# ioam3358 register map
Registers are 32-bit, access not given, no defined reset value unless marked. A register's access mark holds for its fields unless they carry their own. Addresses are absolute; registers are grouped by the start of their names; [hi:lo] are bit positions.

## USB0
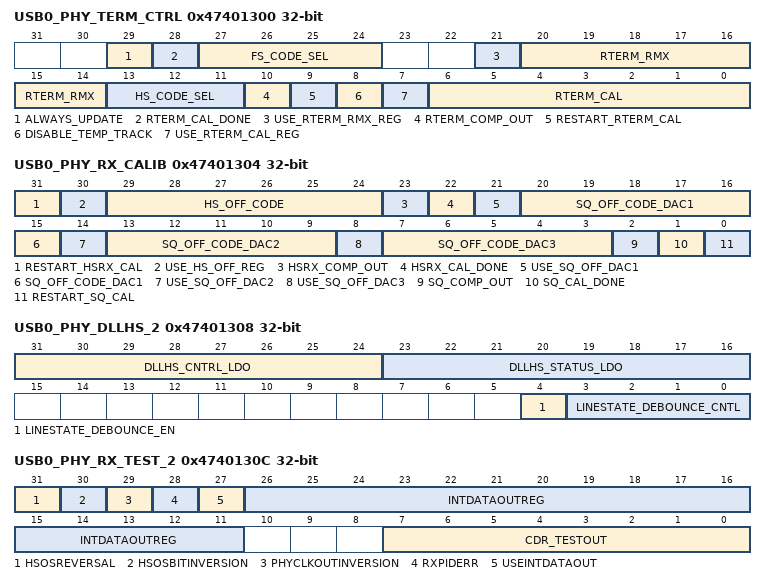
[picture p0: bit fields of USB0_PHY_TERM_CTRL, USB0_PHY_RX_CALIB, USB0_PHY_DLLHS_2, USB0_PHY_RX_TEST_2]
0x47401300 USB0_PHY_TERM_CTRL
  [29] ALWAYS_UPDATE, [28] RTERM_CAL_DONE, [27:24] FS_CODE_SEL, [21] USE_RTERM_RMX_REG, [20:14] RTERM_RMX, [13:11] HS_CODE_SEL, [10] RTERM_COMP_OUT, [9] RESTART_RTERM_CAL, [8] DISABLE_TEMP_TRACK, [7] USE_RTERM_CAL_REG, [6:0] RTERM_CAL
0x47401304 USB0_PHY_RX_CALIB
  [31] RESTART_HSRX_CAL, [30] USE_HS_OFF_REG, [29:24] HS_OFF_CODE, [23] HSRX_COMP_OUT, [22] HSRX_CAL_DONE, [21] USE_SQ_OFF_DAC1, [20:15] SQ_OFF_CODE_DAC1, [14] USE_SQ_OFF_DAC2, [13:9] SQ_OFF_CODE_DAC2, [8] USE_SQ_OFF_DAC3, [7:3] SQ_OFF_CODE_DAC3, [2] SQ_COMP_OUT, [1] SQ_CAL_DONE, [0] RESTART_SQ_CAL
0x47401308 USB0_PHY_DLLHS_2
  [31:24] DLLHS_CNTRL_LDO, [23:16] DLLHS_STATUS_LDO, [4] LINESTATE_DEBOUNCE_EN, [3:0] LINESTATE_DEBOUNCE_CNTL
0x4740130C USB0_PHY_RX_TEST_2
  [31] HSOSREVERSAL, [30] HSOSBITINVERSION, [29] PHYCLKOUTINVERSION, [28] RXPIDERR, [27] USEINTDATAOUT, [26:11] INTDATAOUTREG, [7:0] CDR_TESTOUT
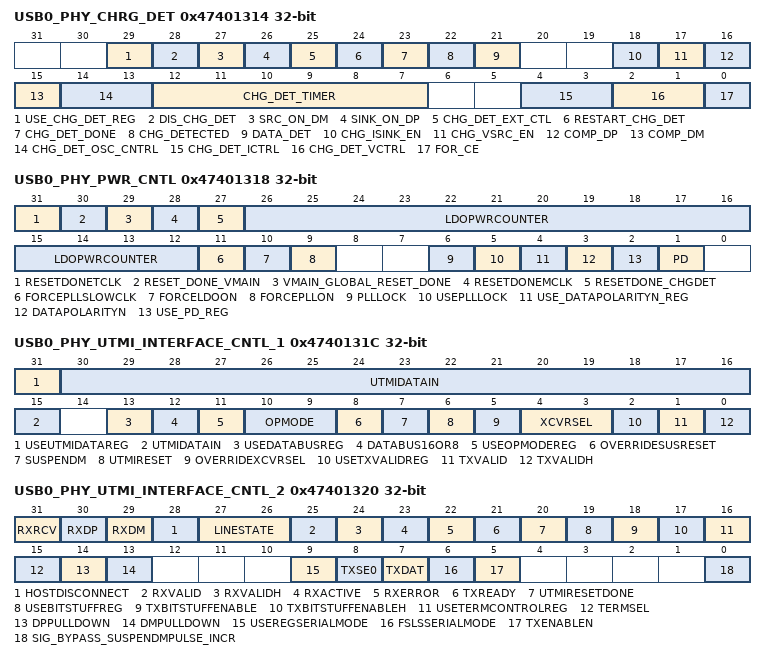
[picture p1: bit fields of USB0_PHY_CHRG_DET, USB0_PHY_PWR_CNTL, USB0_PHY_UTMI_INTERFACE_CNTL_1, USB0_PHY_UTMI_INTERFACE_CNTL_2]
0x47401314 USB0_PHY_CHRG_DET
  [29] USE_CHG_DET_REG, [28] DIS_CHG_DET, [27] SRC_ON_DM, [26] SINK_ON_DP, [25] CHG_DET_EXT_CTL, [24] RESTART_CHG_DET, [23] CHG_DET_DONE, [22] CHG_DETECTED, [21] DATA_DET, [18] CHG_ISINK_EN, [17] CHG_VSRC_EN, [16] COMP_DP, [15] COMP_DM, [14:13] CHG_DET_OSC_CNTRL, [12:7] CHG_DET_TIMER, [4:3] CHG_DET_ICTRL, [2:1] CHG_DET_VCTRL, [0] FOR_CE
0x47401318 USB0_PHY_PWR_CNTL
  [31] RESETDONETCLK, [30] RESET_DONE_VMAIN, [29] VMAIN_GLOBAL_RESET_DONE, [28] RESETDONEMCLK, [27] RESETDONE_CHGDET, [26:12] LDOPWRCOUNTER, [11] FORCEPLLSLOWCLK, [10] FORCELDOON, [9] FORCEPLLON, [6] PLLLOCK, [5] USEPLLLOCK, [4] USE_DATAPOLARITYN_REG, [3] DATAPOLARITYN, [2] USE_PD_REG, [1] PD
0x4740131C USB0_PHY_UTMI_INTERFACE_CNTL_1
  [31] USEUTMIDATAREG, [30:15] UTMIDATAIN, [13] USEDATABUSREG, [12] DATABUS16OR8, [11] USEOPMODEREG, [10:9] OPMODE, [8] OVERRIDESUSRESET, [7] SUSPENDM, [6] UTMIRESET, [5] OVERRIDEXCVRSEL, [4:3] XCVRSEL, [2] USETXVALIDREG, [1] TXVALID, [0] TXVALIDH
0x47401320 USB0_PHY_UTMI_INTERFACE_CNTL_2
  [31] RXRCV, [30] RXDP, [29] RXDM, [28] HOSTDISCONNECT, [27:26] LINESTATE, [25] RXVALID, [24] RXVALIDH, [23] RXACTIVE, [22] RXERROR, [21] TXREADY, [20] UTMIRESETDONE, [19] USEBITSTUFFREG, [18] TXBITSTUFFENABLE, [17] TXBITSTUFFENABLEH, [16] USETERMCONTROLREG, [15] TERMSEL, [14] DPPULLDOWN, [13] DMPULLDOWN, [9] USEREGSERIALMODE, [8] TXSE0, [7] TXDAT, [6] FSLSSERIALMODE, [5] TXENABLEN, [0] SIG_BYPASS_SUSPENDMPULSE_INCR
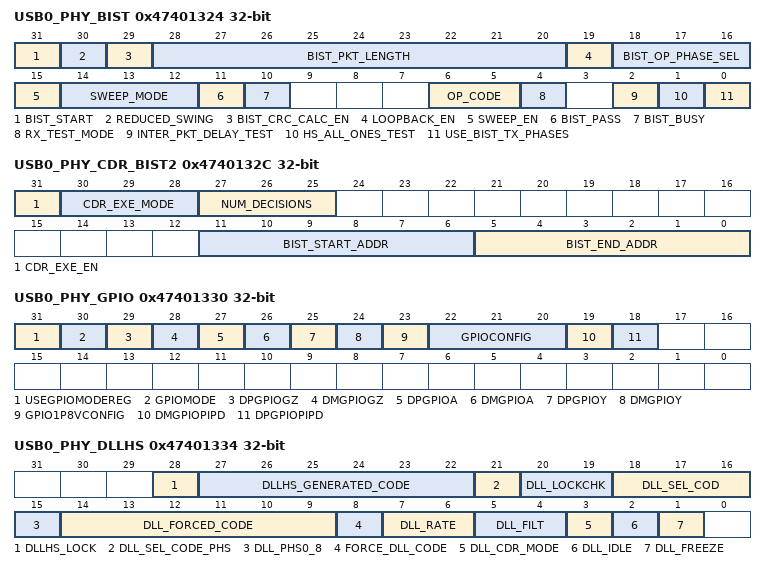
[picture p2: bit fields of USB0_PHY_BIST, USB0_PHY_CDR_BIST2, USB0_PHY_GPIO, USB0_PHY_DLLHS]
0x47401324 USB0_PHY_BIST
  [31] BIST_START, [30] REDUCED_SWING, [29] BIST_CRC_CALC_EN, [28:20] BIST_PKT_LENGTH, [19] LOOPBACK_EN, [18:16] BIST_OP_PHASE_SEL, [15] SWEEP_EN, [14:12] SWEEP_MODE, [11] BIST_PASS, [10] BIST_BUSY, [6:5] OP_CODE, [4] RX_TEST_MODE, [2] INTER_PKT_DELAY_TEST, [1] HS_ALL_ONES_TEST, [0] USE_BIST_TX_PHASES
0x47401328 USB0_PHY_BIST_CRC
0x4740132C USB0_PHY_CDR_BIST2
  [31] CDR_EXE_EN, [30:28] CDR_EXE_MODE, [27:25] NUM_DECISIONS, [11:6] BIST_START_ADDR, [5:0] BIST_END_ADDR
0x47401330 USB0_PHY_GPIO
  [31] USEGPIOMODEREG, [30] GPIOMODE, [29] DPGPIOGZ, [28] DMGPIOGZ, [27] DPGPIOA, [26] DMGPIOA, [25] DPGPIOY, [24] DMGPIOY, [23] GPIO1P8VCONFIG, [22:20] GPIOCONFIG, [19] DMGPIOPIPD, [18] DPGPIOPIPD
0x47401334 USB0_PHY_DLLHS
  [28] DLLHS_LOCK, [27:22] DLLHS_GENERATED_CODE, [21] DLL_SEL_CODE_PHS, [20:19] DLL_LOCKCHK, [18:16] DLL_SEL_COD, [15] DLL_PHS0_8, [14:9] DLL_FORCED_CODE, [8] FORCE_DLL_CODE, [7:6] DLL_RATE, [5:4] DLL_FILT, [3] DLL_CDR_MODE, [2] DLL_IDLE, [1] DLL_FREEZE
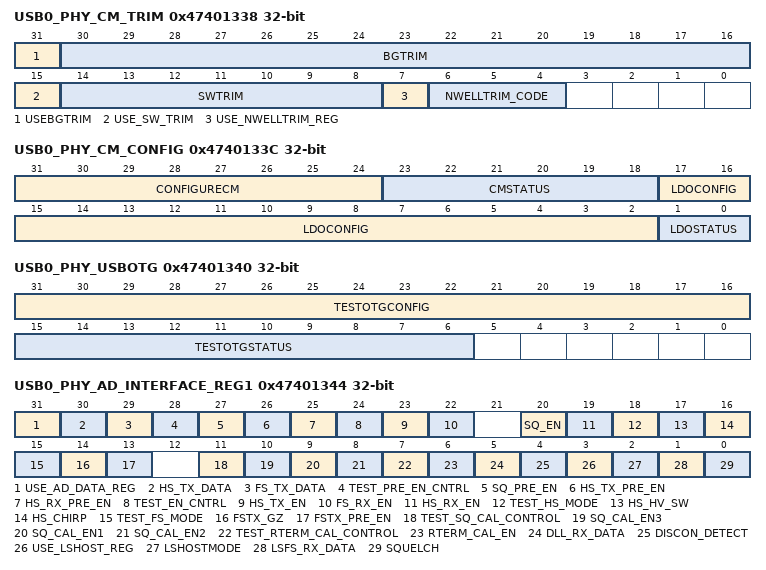
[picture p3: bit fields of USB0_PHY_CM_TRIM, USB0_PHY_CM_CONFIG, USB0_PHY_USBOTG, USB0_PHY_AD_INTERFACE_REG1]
0x47401338 USB0_PHY_CM_TRIM
  [31] USEBGTRIM, [30:16] BGTRIM, [15] USE_SW_TRIM, [14:8] SWTRIM, [7] USE_NWELLTRIM_REG, [6:4] NWELLTRIM_CODE
0x4740133C USB0_PHY_CM_CONFIG
  [31:24] CONFIGURECM, [23:18] CMSTATUS, [17:2] LDOCONFIG, [1:0] LDOSTATUS
0x47401340 USB0_PHY_USBOTG
  [31:16] TESTOTGCONFIG, [15:6] TESTOTGSTATUS
0x47401344 USB0_PHY_AD_INTERFACE_REG1
  [31] USE_AD_DATA_REG, [30] HS_TX_DATA, [29] FS_TX_DATA, [28] TEST_PRE_EN_CNTRL, [27] SQ_PRE_EN, [26] HS_TX_PRE_EN, [25] HS_RX_PRE_EN, [24] TEST_EN_CNTRL, [23] HS_TX_EN, [22] FS_RX_EN, [20] SQ_EN, [19] HS_RX_EN, [18] TEST_HS_MODE, [17] HS_HV_SW, [16] HS_CHIRP, [15] TEST_FS_MODE, [14] FSTX_GZ, [13] FSTX_PRE_EN, [11] TEST_SQ_CAL_CONTROL, [10] SQ_CAL_EN3, [9] SQ_CAL_EN1, [8] SQ_CAL_EN2, [7] TEST_RTERM_CAL_CONTROL, [6] RTERM_CAL_EN, [5] DLL_RX_DATA, [4] DISCON_DETECT, [3] USE_LSHOST_REG, [2] LSHOSTMODE, [1] LSFS_RX_DATA, [0] SQUELCH
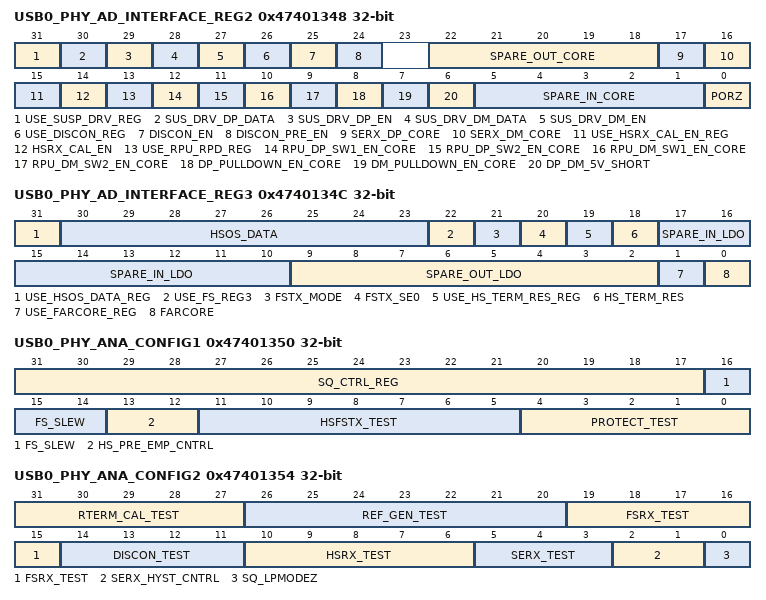
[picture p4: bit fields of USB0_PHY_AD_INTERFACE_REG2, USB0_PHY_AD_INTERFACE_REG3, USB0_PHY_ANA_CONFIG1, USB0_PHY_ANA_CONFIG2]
0x47401348 USB0_PHY_AD_INTERFACE_REG2
  [31] USE_SUSP_DRV_REG, [30] SUS_DRV_DP_DATA, [29] SUS_DRV_DP_EN, [28] SUS_DRV_DM_DATA, [27] SUS_DRV_DM_EN, [26] USE_DISCON_REG, [25] DISCON_EN, [24] DISCON_PRE_EN, [22:18] SPARE_OUT_CORE, [17] SERX_DP_CORE, [16] SERX_DM_CORE, [15] USE_HSRX_CAL_EN_REG, [14] HSRX_CAL_EN, [13] USE_RPU_RPD_REG, [12] RPU_DP_SW1_EN_CORE, [11] RPU_DP_SW2_EN_CORE, [10] RPU_DM_SW1_EN_CORE, [9] RPU_DM_SW2_EN_CORE, [8] DP_PULLDOWN_EN_CORE, [7] DM_PULLDOWN_EN_CORE, [6] DP_DM_5V_SHORT, [5:1] SPARE_IN_CORE, [0] PORZ
0x4740134C USB0_PHY_AD_INTERFACE_REG3
  [31] USE_HSOS_DATA_REG, [30:23] HSOS_DATA, [22] USE_FS_REG3, [21] FSTX_MODE, [20] FSTX_SE0, [19] USE_HS_TERM_RES_REG, [18] HS_TERM_RES, [17:10] SPARE_IN_LDO, [9:2] SPARE_OUT_LDO, [1] USE_FARCORE_REG, [0] FARCORE
0x47401350 USB0_PHY_ANA_CONFIG1
  [31:17] SQ_CTRL_REG, [16:14] FS_SLEW, [13:12] HS_PRE_EMP_CNTRL, [11:5] HSFSTX_TEST, [4:0] PROTECT_TEST
0x47401354 USB0_PHY_ANA_CONFIG2
  [31:27] RTERM_CAL_TEST, [26:20] REF_GEN_TEST, [19:15] FSRX_TEST, [14:11] DISCON_TEST, [10:6] HSRX_TEST, [5:3] SERX_TEST, [2:1] SERX_HYST_CNTRL, [0] SQ_LPMODEZ
